# AT32F403 register map
Vendor: Keil; Series: AT32F403; File version: 1.0
CPU: CM4 r0p1, little endian, no MPU, FPU, 4 interrupt priority bits
Registers are 32-bit, read-write, reset 0x0 unless marked. A register's access mark holds for its fields unless they carry their own. Offsets are from the block's base; [hi:lo] are bit positions; {n}, {i} and the like mark numbered series.

## IOMUX — IO MUX function
Base 0x40010000
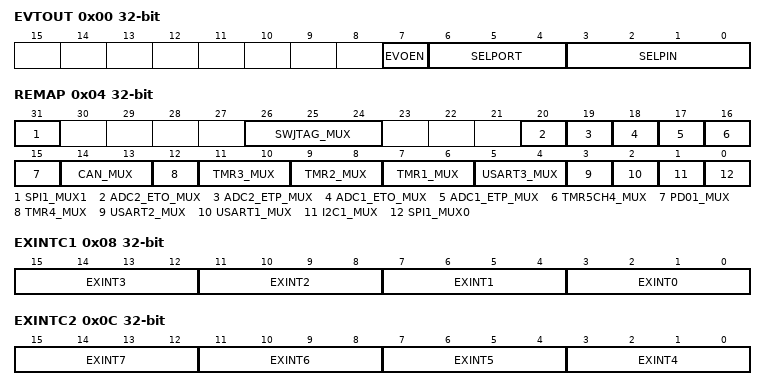
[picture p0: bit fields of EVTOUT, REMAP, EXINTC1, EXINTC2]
0x00 EVTOUT — Event output register (IOMUX_EVTOUT)
  [7] EVOEN — Event output enable
    0=Disable; 1=Enable
  [6:4] SELPORT — Select port
    0=GPIOA; 1=GPIOB; 2=GPIOC; 3=GPIOD; 5=GPIOE; 6=GPIOF; 7=GPIOG
  [3:0] SELPIN — Select pin
0x04 REMAP — IO MUX remap register (IOMUX_REMAP)
  [31] SPI1_MUX1 — SPI1 muxing bit1
  [26:24] SWJTAG_MUX — SWD JTAG muxing
  [20] ADC2_ETO_MUX — ADC2 external trigger ordinary conversion muxing
  [19] ADC2_ETP_MUX — ADC2 external trigger preempted conversion muxing
  [18] ADC1_ETO_MUX — ADC1 external trigger ordinary conversion muxing
  [17] ADC1_ETP_MUX — ADC1 external trigger preempted conversion muxing
  [16] TMR5CH4_MUX — TMR5 channel4 internal muxing
  [15] PD01_MUX — PD0/PD1 muxing on OSCIN/OSCOUT
  [14:13] CAN_MUX — CAN1 muxing
  [12] TMR4_MUX — TMR4 muxing
  [11:10] TMR3_MUX — TMR3 muxing
  [9:8] TMR2_MUX — TMR2 muxing
  [7:6] TMR1_MUX — TMR1 muxing
  [5:4] USART3_MUX — USART3 muxing
  [3] USART2_MUX — USART2 muxing
  [2] USART1_MUX — USART1 muxing
  [1] I2C1_MUX — I2C1 muxing
  [0] SPI1_MUX0 — SPI1 muxing bit0
0x08 EXINTC1 — External interrupt configuration register 1 (IOMUX_EXINTC1)
  [4n+3:4n] EXINT{n} (n=0..3) — Configure EXINT{n} source
0x0C EXINTC2 — External interrupt configuration register 2 (IOMUX_EXINTC2)
  [4n-13:4n-16] EXINT{n} (n=4..7) — Configure EXINT{n} source
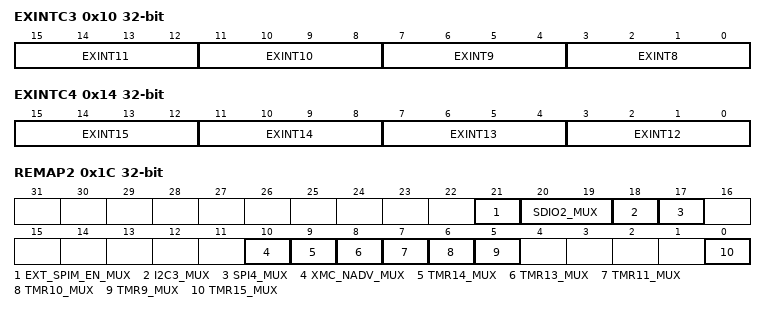
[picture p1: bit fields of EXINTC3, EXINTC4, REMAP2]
0x10 EXINTC3 — External interrupt configuration register 3 (IOMUX_EXINTC3)
  [4n-29:4n-32] EXINT{n} (n=8..11) — Configure EXINT{n} source
0x14 EXINTC4 — External interrupt configuration register 4 (IOMUX_EXINTC4)
  [4n-45:4n-48] EXINT{n} (n=12..15) — Configure EXINT{n} source
0x1C REMAP2 — IO MUX remap register 2 (IOMUX_REMAP2)
  [21] EXT_SPIM_EN_MUX — SPIM enable muxing
  [20:19] SDIO2_MUX — SDIO2 muxing
  [18] I2C3_MUX — I2C3 muxing
  [17] SPI4_MUX — SPI4 muxing
  [10] XMC_NADV_MUX — NADV connect/disconnect
  [9] TMR14_MUX — TMR14 muxing
  [8] TMR13_MUX — TMR13 muxing
  [7] TMR11_MUX — TMR11 muxing
  [6] TMR10_MUX — TMR10 muxing
  [5] TMR9_MUX — TMR9 muxing
  [0] TMR15_MUX — TMR15 muxing

## EXINT
Base 0x40010400
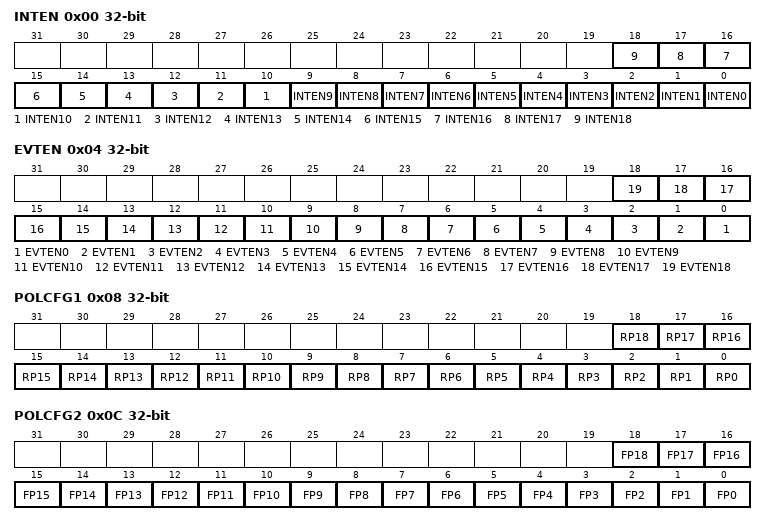
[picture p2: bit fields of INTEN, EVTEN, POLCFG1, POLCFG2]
0x00 INTEN — Interrupt enable register
  [n] INTEN{n} (n=0..18) — Interrupt enable or disable on line {n}
0x04 EVTEN — Event enable register
  [n] EVTEN{n} (n=0..18) — Event enable or disable on line {n}
0x08 POLCFG1 — Rising polarity configuration register
  [n] RP{n} (n=7..18) — Rising polarity configuration bit of line {n}
  [6] RP6 — Rising polarity configuration bit of linee 6
  [n] RP{n} (n=0..5) — Rising polarity configuration bit of line {n}
0x0C POLCFG2 — Falling polarity configuration register
  [n] FP{n} (n=0..18) — Falling polarity event configuration bit of line {n}
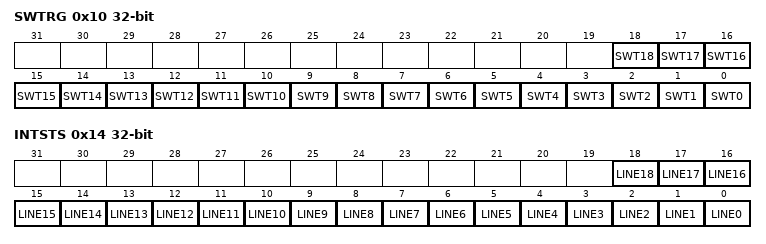
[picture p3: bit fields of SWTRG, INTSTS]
0x10 SWTRG — Software triggle register
  [n] SWT{n} (n=0..18) — Software triggle on line {n}
0x14 INTSTS — Interrupt status register
  [n] LINE{n} (n=0..18) — Line {n} state bit

## RTC — Real time clock
Base 0x40002800
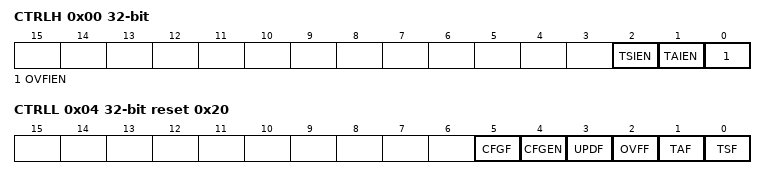
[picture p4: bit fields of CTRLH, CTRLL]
0x00 CTRLH — RTC Control Register High
  [2] TSIEN — Time second interrupt enable
  [1] TAIEN — Time alarm interrupt enable
  [0] OVFIEN — Overflow interrupt enable
0x04 CTRLL reset 0x20 — RTC Control Register Low
  [5] CFGF ro — RTC configuration finish
  [4] CFGEN — RTC configuration enable
  [3] UPDF — RTC update finish
  [2] OVFF — Overflow Flag
  [1] TAF — Time alarm flag
  [0] TSF — Time second flag
0x08 DIVH wo — RTC Divider Register High
  [3:0] DIV — RTC divider high
0x0C DIVL wo reset 0x8000 — RTC Divider Register Low
  [15:0] DIV — RTC divider low
0x10 DIVCNTH — RTC Divider Register High
  [3:0] DIVCNT — RTC divider register high
0x14 DIVCNTL reset 0x8000 — RTC Divider Register Low
  [15:0] DIVCNT — RTC divider register low
0x18 CNTH — RTC Counter Register High
  [15:0] CNT — RTC counter register high
0x1C CNTL — RTC Counter Register Low
  [15:0] CNT — RTC counter register low
0x20 TAH wo reset 0xFFFF — RTC Alarm Register High
  [15:0] TA — Time alarm register high
0x24 TAL wo reset 0xFFFF — Time alarm register low
  [15:0] TA — RTC alarm register low
